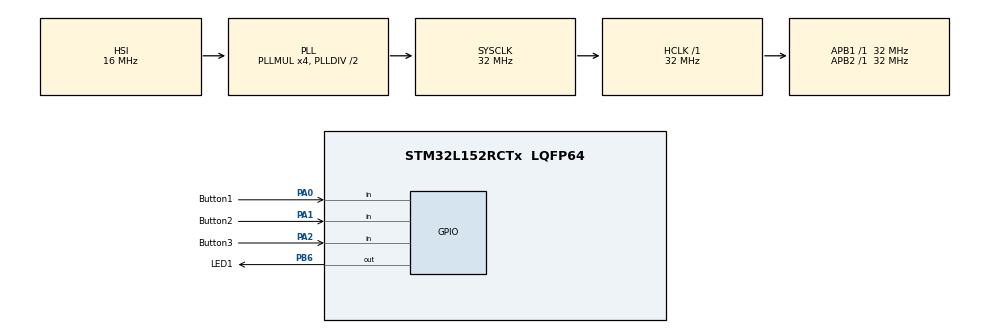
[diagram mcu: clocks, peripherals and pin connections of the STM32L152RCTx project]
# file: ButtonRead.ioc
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Mcu.Family=STM32L1
Mcu.Name=STM32L152RCTx
Mcu.Package=LQFP64
NVIC.PriorityGroup=NVIC_PRIORITYGROUP_4
PA0-WKUP1.GPIO_Label=Button1
PA0-WKUP1.Signal=GPIO_Input
PA1.GPIO_Label=Button2
PA1.Signal=GPIO_Input
PA13.Mode=Serial_Wire
PA13.Signal=SYS_JTMS-SWDIO
PA14.Mode=Serial_Wire
PA14.Signal=SYS_JTCK-SWCLK
PA2.GPIO_Label=Button3
PA2.Signal=GPIO_Input
PB6.GPIO_Label=LED1
PB6.Signal=GPIO_Output
ProjectManager.HeapSize=0x200
ProjectManager.StackSize=0x400
ProjectManager.TargetToolchain=STM32CubeIDE
RCC.48MHZClocksFreq_Value=32000000
RCC.AHBFreq_Value=32000000
RCC.APB1Freq_Value=32000000
RCC.APB1TimFreq_Value=32000000
RCC.APB2Freq_Value=32000000
RCC.APB2TimFreq_Value=32000000
RCC.HCLKFreq_Value=32000000
RCC.HSE_VALUE=24000000
RCC.HSI_VALUE=16000000
RCC.LSE_VALUE=32768
RCC.MSI_VALUE=2097000
RCC.PLLMUL=RCC_PLL_MUL4
RCC.SYSCLKFreq_VALUE=32000000
RCC.SYSCLKSource=RCC_SYSCLKSOURCE_PLLCLK
RCC.VCOOutputFreq_Value=64000000
TIM10.AutoReloadPreload=TIM_AUTORELOAD_PRELOAD_ENABLE
TIM10.Period=32000
TIM10.Prescaler=1
VP_TIM10_VS_ClockSourceINT.Mode=Internal
board=custom

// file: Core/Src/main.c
/* USER CODE BEGIN Header */
/**
  ******************************************************************************
  * @file           : main.c
  * @brief          : Main program body
  ******************************************************************************
  * @attention
  *
  * Copyright (c) 2024 STMicroelectronics.
  * All rights reserved.
  *
  * This software is licensed under terms that can be found in the LICENSE file
  * in the root directory of this software component.
  * If no LICENSE file comes with this software, it is provided AS-IS.
  *
  ******************************************************************************
  */
/* USER CODE END Header */
#include "main.h"
#include "tim.h"
#include "gpio.h"

/* USER CODE BEGIN Includes */
#include"Button.h"
/* USER CODE END Includes */

/* USER CODE BEGIN PD */
#define TRUE   1U
#define FALSE  0U
/* USER CODE END PD */

/* USER CODE BEGIN PV */
uint32_t u32_SystemCNT  = 0;
uint8_t  u8_sysTickFlag = 0;
/* USER CODE END PV */

void SystemClock_Config(void);

int main(void)
{

  /* MCU Configuration--------------------------------------------------------*/

  /* Reset of all peripherals, Initializes the Flash interface and the Systick. */
  HAL_Init();

  /* Configure the system clock */
  SystemClock_Config();

  /* Initialize all configured peripherals */
  MX_GPIO_Init();
  MX_TIM10_Init();
  /* USER CODE BEGIN 2 */
  ButtonInitTask();

  /* USER CODE END 2 */

  /* Infinite loop */
  /* USER CODE BEGIN WHILE */
  while (1)
  {

	  if((__HAL_TIM_GetCounter(&htim10) %1) ==0)
	  {
		  ButtonMainTask();
	  }
	  if((__HAL_TIM_GetCounter(&htim10) %1000) ==0)
	  {

		 __HAL_TIM_SetCounter(&htim10,0);

	  }

    /* USER CODE END WHILE */

  }
}

void SystemClock_Config(void)
{
  RCC_OscInitTypeDef RCC_OscInitStruct = {0};
  RCC_ClkInitTypeDef RCC_ClkInitStruct = {0};

  /** Configure the main internal regulator output voltage
  */
  __HAL_PWR_VOLTAGESCALING_CONFIG(PWR_REGULATOR_VOLTAGE_SCALE1);

  /** Initializes the RCC Oscillators according to the specified parameters
  * in the RCC_OscInitTypeDef structure.
  */
  RCC_OscInitStruct.OscillatorType = RCC_OSCILLATORTYPE_HSI;
  RCC_OscInitStruct.HSIState = RCC_HSI_ON;
  RCC_OscInitStruct.HSICalibrationValue = RCC_HSICALIBRATION_DEFAULT;
  RCC_OscInitStruct.PLL.PLLState = RCC_PLL_ON;
  RCC_OscInitStruct.PLL.PLLSource = RCC_PLLSOURCE_HSI;
  RCC_OscInitStruct.PLL.PLLMUL = RCC_PLL_MUL4;
  RCC_OscInitStruct.PLL.PLLDIV = RCC_PLL_DIV2;
  if (HAL_RCC_OscConfig(&RCC_OscInitStruct) != HAL_OK)
  {
    Error_Handler();
  }

  /** Initializes the CPU, AHB and APB buses clocks
  */
  RCC_ClkInitStruct.ClockType = RCC_CLOCKTYPE_HCLK|RCC_CLOCKTYPE_SYSCLK
                              |RCC_CLOCKTYPE_PCLK1|RCC_CLOCKTYPE_PCLK2;
  RCC_ClkInitStruct.SYSCLKSource = RCC_SYSCLKSOURCE_PLLCLK;
  RCC_ClkInitStruct.AHBCLKDivider = RCC_SYSCLK_DIV1;
  RCC_ClkInitStruct.APB1CLKDivider = RCC_HCLK_DIV1;
  RCC_ClkInitStruct.APB2CLKDivider = RCC_HCLK_DIV1;

  if (HAL_RCC_ClockConfig(&RCC_ClkInitStruct, FLASH_LATENCY_1) != HAL_OK)
  {
    Error_Handler();
  }
}

/* USER CODE BEGIN 4 */

/**
  * @brief  SYSTICK callback.
  * @retval None
  */
void HAL_SYSTICK_Callback(void)
{

	u8_sysTickFlag = TRUE;
}

/* USER CODE END 4 */

void Error_Handler(void)
{
  __disable_irq();
  while (1)
  {
  }
}
